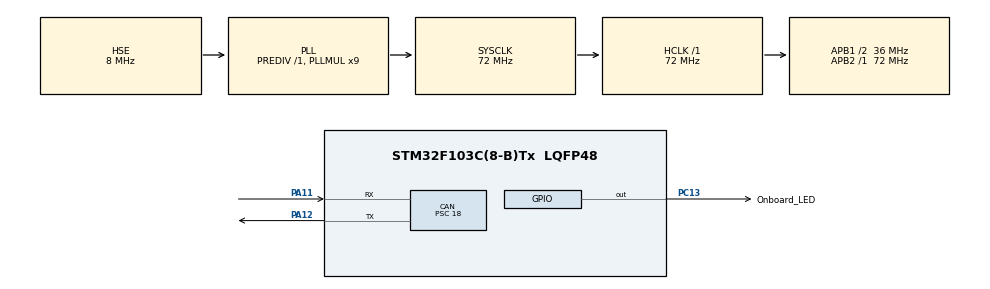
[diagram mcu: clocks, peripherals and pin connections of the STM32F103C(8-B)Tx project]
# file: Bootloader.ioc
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CAN.BS1=CAN_BS1_13TQ
CAN.BS2=CAN_BS2_2TQ
CAN.CalculateTimeBit=1500
CAN.CalculateTimeQuantum=500.0
CAN.NART=DISABLE
CAN.Prescaler=18
CAN.TXFP=ENABLE
Mcu.Family=STM32F1
Mcu.Name=STM32F103C(8-B)Tx
Mcu.Package=LQFP48
NVIC.CAN1_RX1_IRQn=true\:0\:0\:false\:false\:true\:true
NVIC.PriorityGroup=NVIC_PRIORITYGROUP_4
NVIC.USB_HP_CAN1_TX_IRQn=true\:0\:0\:false\:false\:true\:true
NVIC.USB_LP_CAN1_RX0_IRQn=true\:0\:0\:false\:false\:true\:true
PA11.Mode=Master
PA11.Signal=CAN_RX
PA12.Mode=Master
PA12.Signal=CAN_TX
PA13.Mode=Serial_Wire
PA13.Signal=SYS_JTMS-SWDIO
PA14.Mode=Serial_Wire
PA14.Signal=SYS_JTCK-SWCLK
PC13-TAMPER-RTC.GPIO_Label=Onboard_LED
PC13-TAMPER-RTC.Signal=GPIO_Output
PD0-OSC_IN.Mode=HSE-External-Oscillator
PD0-OSC_IN.Signal=RCC_OSC_IN
PD1-OSC_OUT.Mode=HSE-External-Oscillator
PD1-OSC_OUT.Signal=RCC_OSC_OUT
ProjectManager.HeapSize=0x200
ProjectManager.StackSize=0x400
ProjectManager.TargetToolchain=MDK-ARM V5
RCC.AHBFreq_Value=72000000
RCC.APB1CLKDivider=RCC_HCLK_DIV2
RCC.APB1Freq_Value=36000000
RCC.APB1TimFreq_Value=72000000
RCC.APB2Freq_Value=72000000
RCC.APB2TimFreq_Value=72000000
RCC.HCLKFreq_Value=72000000
RCC.PLLMUL=RCC_PLL_MUL9
RCC.PLLSourceVirtual=RCC_PLLSOURCE_HSE
RCC.SYSCLKFreq_VALUE=72000000
RCC.SYSCLKSource=RCC_SYSCLKSOURCE_PLLCLK
RCC.USBFreq_Value=72000000
board=CAN

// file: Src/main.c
/**
  ******************************************************************************
  * @file           : main.c
  * @brief          : Main program body
  ******************************************************************************
  ** This notice applies to any and all portions of this file
  * that are not between comment pairs USER CODE BEGIN and
  * USER CODE END. Other portions of this file, whether
  * inserted by the user or by software development tools
  * are owned by their respective copyright owners.
  *
  * COPYRIGHT(c) 2019 STMicroelectronics
  *
  * Redistribution and use in source and binary forms, with or without modification,
  * are permitted provided that the following conditions are met:
  *   1. Redistributions of source code must retain the above copyright notice,
  *      this list of conditions and the following disclaimer.
  *   2. Redistributions in binary form must reproduce the above copyright notice,
  *      this list of conditions and the following disclaimer in the documentation
  *      and/or other materials provided with the distribution.
  *   3. Neither the name of STMicroelectronics nor the names of its contributors
  *      may be used to endorse or promote products derived from this software
  *      without specific prior written permission.
  *
  * THIS SOFTWARE IS PROVIDED BY THE COPYRIGHT HOLDERS AND CONTRIBUTORS "AS IS"
  * AND ANY EXPRESS OR IMPLIED WARRANTIES, INCLUDING, BUT NOT LIMITED TO, THE
  * IMPLIED WARRANTIES OF MERCHANTABILITY AND FITNESS FOR A PARTICULAR PURPOSE ARE
  * DISCLAIMED. IN NO EVENT SHALL THE COPYRIGHT HOLDER OR CONTRIBUTORS BE LIABLE
  * FOR ANY DIRECT, INDIRECT, INCIDENTAL, SPECIAL, EXEMPLARY, OR CONSEQUENTIAL
  * DAMAGES (INCLUDING, BUT NOT LIMITED TO, PROCUREMENT OF SUBSTITUTE GOODS OR
  * SERVICES; LOSS OF USE, DATA, OR PROFITS; OR BUSINESS INTERRUPTION) HOWEVER
  * CAUSED AND ON ANY THEORY OF LIABILITY, WHETHER IN CONTRACT, STRICT LIABILITY,
  * OR TORT (INCLUDING NEGLIGENCE OR OTHERWISE) ARISING IN ANY WAY OUT OF THE USE
  * OF THIS SOFTWARE, EVEN IF ADVISED OF THE POSSIBILITY OF SUCH DAMAGE.
  *
  ******************************************************************************
  */
#include "main.h"
#include "stm32f1xx_hal.h"

/* USER CODE BEGIN Includes */
#include "FLASHMemoryMap.h"
#include "NVRAM.h"
#include "IridiumCRC16.h"

/* USER CODE END Includes */

CAN_HandleTypeDef hcan;

/* USER CODE BEGIN PV */
/* Private variables ---------------------------------------------------------*/

/* USER CODE END PV */

void SystemClock_Config(void);
static void MX_GPIO_Init(void);
static void MX_CAN_Init(void);

/* USER CODE BEGIN PFP */
/* Private function prototypes -----------------------------------------------*/

/* USER CODE END PFP */

/* USER CODE BEGIN 0 */
//////////////////////////////////////////////////////////////////////////
// Связывание C и CPP кода
//////////////////////////////////////////////////////////////////////////
// Процедуры
extern void iRidiumDevice_InitEEPROM(void);
extern void iRidiumDevice_Setup(void);
extern void iRidiumDevice_Loop(void);

/* USER CODE END 0 */

int main(void)
{
  /* USER CODE BEGIN 1 */
   GPIO_InitTypeDef GPIO_InitStruct;

   // GPIO Ports Clock Enable
   __HAL_RCC_GPIOB_CLK_ENABLE();

   // Configure GPIO pin : Onboard_Button_Pin
   GPIO_InitStruct.Pin = Onboard_Button_Pin;
   GPIO_InitStruct.Mode = GPIO_MODE_INPUT;
   GPIO_InitStruct.Pull = GPIO_PULLUP;
   HAL_GPIO_Init(Onboard_Button_GPIO_Port, &GPIO_InitStruct);

   //ссылка на структуру памяти eeprom_common_t под именем l_pEEPROM = (приводим тип к этой же структуре) + начало памяти
   nvram_common_t* l_pEEPROM = (nvram_common_t*)EEPROM_FLASH_START;
   // Получение режима работы, размера текущей прошивки и ее контрольную сумму
   eBootloaderMode l_eMode = (eBootloaderMode)l_pEEPROM->m_u8Mode;
   u32 l_u32Size = l_pEEPROM->m_u32FirmwareSize;
   u16 l_u16CRC = l_pEEPROM->m_u16FirmwareCRC16;

   // Если набортная кнопка не зажата, пробуем запустить прошивку
   if(GPIO_PIN_SET == HAL_GPIO_ReadPin(Onboard_Button_GPIO_Port, Onboard_Button_Pin))
   {
      // Если нужна загрузка или сброс прошивки
      if(l_eMode == BOOTLOADER_MODE_RUN)
      {
         // Проверка размера и контрольной суммы прошивки
         if(l_u32Size && l_u32Size <= FIRMWARE_SIZE && GetCRC16Modbus(0x77, (u8*)FIRMWARE_START, l_u32Size) == l_u16CRC)
         {
            // Прототип функции
            typedef void (*function_t)();

            // Запрет прерывания
            __disable_irq();

            // �?зменение вектора прерываний
            SCB->VTOR = FIRMWARE_START;

            // Вычисление указателя на прошивку
            u32 l_u32JumpAddress = *(__IO uint32_t*)(FIRMWARE_START + 4);
            function_t l_pJumpPtr = (function_t)l_u32JumpAddress;

            // �?зменение указателя стека
            __set_MSP(*(__IO uint32_t*)FIRMWARE_START);

            // Переход в прошивку
            l_pJumpPtr();
         }
      }
   }

  /* USER CODE END 1 */

  /* MCU Configuration----------------------------------------------------------*/

  /* Reset of all peripherals, Initializes the Flash interface and the Systick. */
  HAL_Init();

  /* Configure the system clock */
  SystemClock_Config();

  /* Initialize all configured peripherals */
  MX_GPIO_Init();
  MX_CAN_Init();
  /* USER CODE BEGIN 2 */
   // Инициализация энегронезависимой памяти
   iRidiumDevice_InitEEPROM();
   // �?нициализация устройства
   iRidiumDevice_Setup();

  /* USER CODE END 2 */

  /* Infinite loop */
  while (1)
  {

  /* USER CODE BEGIN 3 */
   iRidiumDevice_Loop();
  }
  /* USER CODE END 3 */

}

void SystemClock_Config(void)
{

  RCC_OscInitTypeDef RCC_OscInitStruct;
  RCC_ClkInitTypeDef RCC_ClkInitStruct;

    /**Initializes the CPU, AHB and APB busses clocks
    */
  RCC_OscInitStruct.OscillatorType = RCC_OSCILLATORTYPE_HSE;
  RCC_OscInitStruct.HSEState = RCC_HSE_ON;
  RCC_OscInitStruct.HSEPredivValue = RCC_HSE_PREDIV_DIV1;
  RCC_OscInitStruct.HSIState = RCC_HSI_ON;
  RCC_OscInitStruct.PLL.PLLState = RCC_PLL_ON;
  RCC_OscInitStruct.PLL.PLLSource = RCC_PLLSOURCE_HSE;
  RCC_OscInitStruct.PLL.PLLMUL = RCC_PLL_MUL9;
  if (HAL_RCC_OscConfig(&RCC_OscInitStruct) != HAL_OK)
  {
    _Error_Handler(__FILE__, __LINE__);
  }

    /**Initializes the CPU, AHB and APB busses clocks
    */
  RCC_ClkInitStruct.ClockType = RCC_CLOCKTYPE_HCLK|RCC_CLOCKTYPE_SYSCLK
                              |RCC_CLOCKTYPE_PCLK1|RCC_CLOCKTYPE_PCLK2;
  RCC_ClkInitStruct.SYSCLKSource = RCC_SYSCLKSOURCE_PLLCLK;
  RCC_ClkInitStruct.AHBCLKDivider = RCC_SYSCLK_DIV1;
  RCC_ClkInitStruct.APB1CLKDivider = RCC_HCLK_DIV2;
  RCC_ClkInitStruct.APB2CLKDivider = RCC_HCLK_DIV1;

  if (HAL_RCC_ClockConfig(&RCC_ClkInitStruct, FLASH_LATENCY_2) != HAL_OK)
  {
    _Error_Handler(__FILE__, __LINE__);
  }

    /**Configure the Systick interrupt time
    */
  HAL_SYSTICK_Config(HAL_RCC_GetHCLKFreq()/1000);

    /**Configure the Systick
    */
  HAL_SYSTICK_CLKSourceConfig(SYSTICK_CLKSOURCE_HCLK);

  /* SysTick_IRQn interrupt configuration */
  HAL_NVIC_SetPriority(SysTick_IRQn, 0, 0);
}

/* CAN init function */
static void MX_CAN_Init(void)
{

  hcan.Instance = CAN1;
  hcan.Init.Prescaler = 18;
  hcan.Init.Mode = CAN_MODE_NORMAL;
  hcan.Init.SJW = CAN_SJW_1TQ;
  hcan.Init.BS1 = CAN_BS1_13TQ;
  hcan.Init.BS2 = CAN_BS2_2TQ;
  hcan.Init.TTCM = DISABLE;
  hcan.Init.ABOM = ENABLE;
  hcan.Init.AWUM = DISABLE;
  hcan.Init.NART = DISABLE;
  hcan.Init.RFLM = ENABLE;
  hcan.Init.TXFP = ENABLE;
  if (HAL_CAN_Init(&hcan) != HAL_OK)
  {
    _Error_Handler(__FILE__, __LINE__);
  }

}

/** Configure pins as
        * Analog
        * Input
        * Output
        * EVENT_OUT
        * EXTI
*/
static void MX_GPIO_Init(void)
{

  GPIO_InitTypeDef GPIO_InitStruct;

  /* GPIO Ports Clock Enable */
  __HAL_RCC_GPIOC_CLK_ENABLE();
  __HAL_RCC_GPIOD_CLK_ENABLE();
  __HAL_RCC_GPIOA_CLK_ENABLE();

  /*Configure GPIO pin Output Level */
  HAL_GPIO_WritePin(Onboard_LED_GPIO_Port, Onboard_LED_Pin, GPIO_PIN_RESET);

  /*Configure GPIO pin : Onboard_LED_Pin */
  GPIO_InitStruct.Pin = Onboard_LED_Pin;
  GPIO_InitStruct.Mode = GPIO_MODE_OUTPUT_PP;
  GPIO_InitStruct.Pull = GPIO_NOPULL;
  GPIO_InitStruct.Speed = GPIO_SPEED_FREQ_LOW;
  HAL_GPIO_Init(Onboard_LED_GPIO_Port, &GPIO_InitStruct);

  /*Configure GPIO pin : Onboard_Button_Pin */
  GPIO_InitStruct.Pin = Onboard_Button_Pin;
  GPIO_InitStruct.Mode = GPIO_MODE_INPUT;
  GPIO_InitStruct.Pull = GPIO_PULLUP;
  HAL_GPIO_Init(Onboard_Button_GPIO_Port, &GPIO_InitStruct);

}

void _Error_Handler(char *file, int line)
{
  while(1)
  {
  }
}

/************************ (C) COPYRIGHT STMicroelectronics *****END OF FILE****/
